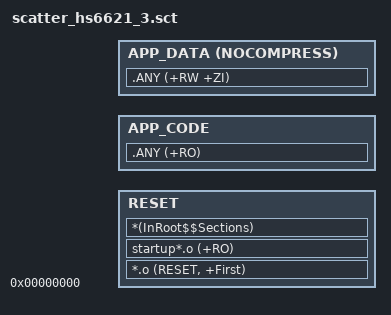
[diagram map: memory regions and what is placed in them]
#! armcc -E
; ***************************************************************
; *** Scatter-Loading Description File generated by Huntersun ***
; ***************************************************************

#define LP_RAM_BASE     0x2001E000
#define LP_RAM_OFFSET   0x0001E000

RAM_LOAD 0x00000000 0x00040000
{
    RESET 0x00000000
    {
        *.o (RESET, +First)
        startup*.o (+RO)
        *(InRoot$$Sections)
    }

    ; force SOME .code to ULP RAM
    ; APP_ULP_CODE +0
    ; {
    ;
    ; }

    APP_CODE +0
    {
        .ANY (+RO)
    }

    ; Force SOME .data and .bss into LP or ULP ram
    APP_DATA 0x20000000 + ImageLimit(APP_CODE) NOCOMPRESS
    {
        .ANY (+RW +ZI)
    }

    ; Force SOME .data and .bss into LP ram
    ; APP AlignExpr((ImageLimit(APP_DATA) > LP_RAM_BASE) ? ImageLimit(APP_DATA) : LP_RAM_BASE, 8) NOCOMPRESS
    ; {
    ;    abc.o (+RW +ZI)
    ; }
}

ScatterAssert(ImageLimit(RESET) < 0x00002000)
ScatterAssert(ImageLimit(APP)   < 0x2003e8a0)

